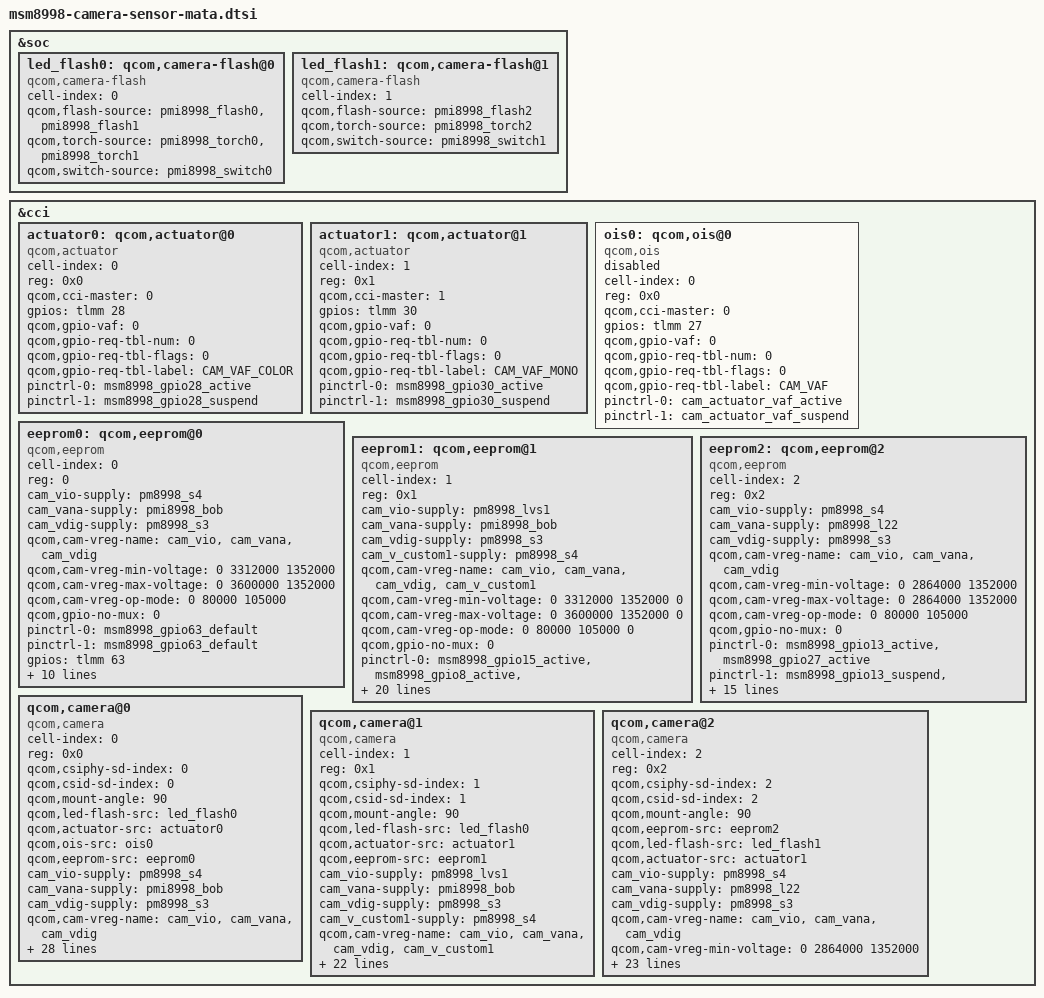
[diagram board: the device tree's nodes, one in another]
/*
 * Copyright (c) 2016, The Linux Foundation. All rights reserved.
 *
 * This program is free software; you can redistribute it and/or modify
 * it under the terms of the GNU General Public License version 2 and
 * only version 2 as published by the Free Software Foundation.
 *
 * This program is distributed in the hope that it will be useful,
 * but WITHOUT ANY WARRANTY; without even the implied warranty of
 * MERCHANTABILITY or FITNESS FOR A PARTICULAR PURPOSE.  See the
 * GNU General Public License for more details.
 */

&soc {
	led_flash0: qcom,camera-flash@0 {
		cell-index = <0>;
		compatible = "qcom,camera-flash";
		qcom,flash-source = <&pmi8998_flash0 &pmi8998_flash1>;
		qcom,torch-source = <&pmi8998_torch0 &pmi8998_torch1>;
		qcom,switch-source = <&pmi8998_switch0>;
		status = "ok";
	};

	led_flash1: qcom,camera-flash@1 {
		cell-index = <1>;
		compatible = "qcom,camera-flash";
		qcom,flash-source = <&pmi8998_flash2>;
		qcom,torch-source = <&pmi8998_torch2>;
		qcom,switch-source = <&pmi8998_switch1>;
		status = "ok";
	};
};

&cci {
	actuator0: qcom,actuator@0 {
		cell-index = <0>;
		reg = <0x0>;
		compatible = "qcom,actuator";
		qcom,cci-master = <0>;
		gpios = <&tlmm 28 0>;
		qcom,gpio-vaf = <0>;
		qcom,gpio-req-tbl-num = <0>;
		qcom,gpio-req-tbl-flags = <0>;
		qcom,gpio-req-tbl-label = "CAM_VAF_COLOR";
		pinctrl-names = "cam_default", "cam_suspend";
		pinctrl-0 = <&msm8998_gpio28_active>;
		pinctrl-1 = <&msm8998_gpio28_suspend>;
	};

	actuator1: qcom,actuator@1 {
		cell-index = <1>;
		reg = <0x1>;
		compatible = "qcom,actuator";
		qcom,cci-master = <1>;
		gpios = <&tlmm 30 0>;
		qcom,gpio-vaf = <0>;
		qcom,gpio-req-tbl-num = <0>;
		qcom,gpio-req-tbl-flags = <0>;
		qcom,gpio-req-tbl-label = "CAM_VAF_MONO";
		pinctrl-names = "cam_default", "cam_suspend";
		pinctrl-0 = <&msm8998_gpio30_active>;
		pinctrl-1 = <&msm8998_gpio30_suspend>;
	};

	ois0: qcom,ois@0 {
		cell-index = <0>;
		reg = <0x0>;
		compatible = "qcom,ois";
		qcom,cci-master = <0>;
		gpios = <&tlmm 27 0>;
		qcom,gpio-vaf = <0>;
		qcom,gpio-req-tbl-num = <0>;
		qcom,gpio-req-tbl-flags = <0>;
		qcom,gpio-req-tbl-label = "CAM_VAF";
		pinctrl-names = "cam_default", "cam_suspend";
		pinctrl-0 = <&cam_actuator_vaf_active>;
		pinctrl-1 = <&cam_actuator_vaf_suspend>;
		status = "disabled";
	};
 
	eeprom0: qcom,eeprom@0 {
		cell-index = <0>;
		reg = <0>;
		compatible = "qcom,eeprom";
		cam_vio-supply = <&pm8998_s4>;
		cam_vana-supply = <&pmi8998_bob>;
		cam_vdig-supply = <&pm8998_s3>;
		qcom,cam-vreg-name = "cam_vio", "cam_vana", "cam_vdig";
		qcom,cam-vreg-min-voltage = <0 3312000 1352000>;
		qcom,cam-vreg-max-voltage = <0 3600000 1352000>;
		qcom,cam-vreg-op-mode = <0 80000 105000>;
		qcom,gpio-no-mux = <0>;
		pinctrl-names = "cam_default", "cam_suspend";
		pinctrl-0 = <&msm8998_gpio63_default>;
		pinctrl-1 = <&msm8998_gpio63_default>;
		gpios =  <&tlmm 63 0>;
		qcom,gpio-vio = <0>;
		qcom,gpio-req-tbl-num = <0>;
		qcom,gpio-req-tbl-flags = <0>;
		qcom,gpio-req-tbl-label = "CAM_VIO";
		qcom,sensor-position = <0>;
		qcom,sensor-mode = <0>;
		qcom,cci-master = <0>;
		status = "ok";
		clocks = <&clock_mmss clk_mclk1_clk_src>,
				<&clock_mmss clk_mmss_camss_mclk1_clk>;
		clock-names = "cam_src_clk", "cam_clk";
		qcom,clock-rates = <24000000 0>;
	};
  
	eeprom1: qcom,eeprom@1 {
		cell-index = <1>;
		reg = <0x1>;
		compatible = "qcom,eeprom";
		cam_vio-supply = <&pm8998_lvs1>;
		cam_vana-supply = <&pmi8998_bob>;
		cam_vdig-supply = <&pm8998_s3>;
		cam_v_custom1-supply = <&pm8998_s4>;
		qcom,cam-vreg-name = "cam_vio", "cam_vana", "cam_vdig", "cam_v_custom1";
		qcom,cam-vreg-min-voltage = <0 3312000 1352000 0>;
		qcom,cam-vreg-max-voltage = <0 3600000 1352000 0>;
		qcom,cam-vreg-op-mode = <0 80000 105000 0>;
		qcom,gpio-no-mux = <0>;
		pinctrl-names = "cam_default", "cam_suspend";
		pinctrl-0 = <&msm8998_gpio15_active
				&msm8998_gpio8_active
				&msm8998_gpio31_default
				&msm8998_gpio90_default>;
		pinctrl-1 = <&msm8998_gpio15_suspend
				&msm8998_gpio8_suspend
				&msm8998_gpio31_default
				&msm8998_gpio90_default>;
		gpios = <&tlmm 15 0>,
			<&tlmm 8 0>,
			<&tlmm 31 0>,
			<&tlmm 90 0>;
		qcom,gpio-reset = <1>;
		qcom,gpio-vana = <2>;
		qcom,gpio-vdig = <3>;
		qcom,gpio-req-tbl-num = <0 1 2 3>;
		qcom,gpio-req-tbl-flags = <1 0 0 0>;
		qcom,gpio-req-tbl-label = "CAMIF_MCLK1",
					"CAM_RESET1",
					"CAM_VANA1",
					"CAM_VDIG1";
		qcom,sensor-position = <0>;
		qcom,sensor-mode = <0>;
		qcom,cci-master = <1>;
		status = "ok";
		clocks = <&clock_mmss clk_mclk2_clk_src>,
				<&clock_mmss clk_mmss_camss_mclk2_clk>;
		clock-names = "cam_src_clk", "cam_clk";
		qcom,clock-rates = <24000000 0>;
	};

	eeprom2: qcom,eeprom@2 {
		cell-index = <2>;
		reg = <0x2>;
		compatible = "qcom,eeprom";
		cam_vio-supply = <&pm8998_s4>;
		cam_vana-supply = <&pm8998_l22>;
		cam_vdig-supply = <&pm8998_s3>;
		qcom,cam-vreg-name = "cam_vio", "cam_vana", "cam_vdig";
		qcom,cam-vreg-min-voltage = <0 2864000 1352000>;
		qcom,cam-vreg-max-voltage = <0 2864000 1352000>;
		qcom,cam-vreg-op-mode = <0 80000 105000>;
		qcom,gpio-no-mux = <0>;
		pinctrl-names = "cam_default", "cam_suspend";
		pinctrl-0 = <&msm8998_gpio13_active
				&msm8998_gpio27_active>;
		pinctrl-1 = <&msm8998_gpio13_suspend
				&msm8998_gpio27_active>;
		gpios = <&tlmm 13 0>,
			<&tlmm 27 0>,
			<&tlmm 9 0>,
			<&tlmm 65 0>;
		qcom,gpio-reset = <1>;
		qcom,gpio-vio = <2>;
		qcom,gpio-vdig = <3>;
		qcom,gpio-req-tbl-num = <0 1 2 3>;
		qcom,gpio-req-tbl-flags = <1 0 0 0>;
		qcom,gpio-req-tbl-label = "CAMIF_MCLK2",
					"CAM_RESET2",
					"CAM_VIO2",
					"CAM_VDIG2";
		qcom,sensor-position = <1>;
		qcom,sensor-mode = <0>;
		qcom,cci-master = <1>;
		status = "ok";
		clocks = <&clock_mmss clk_mclk0_clk_src>,
				<&clock_mmss clk_mmss_camss_mclk0_clk>;
		clock-names = "cam_src_clk", "cam_clk";
		qcom,clock-rates = <24000000 0>;
	};
 
	qcom,camera@0 {
		cell-index = <0>;
		compatible = "qcom,camera";
		reg = <0x0>;
		qcom,csiphy-sd-index = <0>;
		qcom,csid-sd-index = <0>;
		qcom,mount-angle = <90>;
		qcom,led-flash-src = <&led_flash0>;
		qcom,actuator-src = <&actuator0>;
		qcom,ois-src = <&ois0>;
		qcom,eeprom-src = <&eeprom0>;
		cam_vio-supply = <&pm8998_s4>;
		cam_vana-supply = <&pmi8998_bob>;
		cam_vdig-supply = <&pm8998_s3>;
		qcom,cam-vreg-name = "cam_vio", "cam_vana", "cam_vdig";
		qcom,cam-vreg-min-voltage = <0 3312000 1352000>;
		qcom,cam-vreg-max-voltage = <0 3600000 1352000>;
		qcom,cam-vreg-op-mode = <0 80000 105000>;
		qcom,gpio-no-mux = <0>;
		pinctrl-names = "cam_default", "cam_suspend";
		pinctrl-0 = <&msm8998_gpio14_active
				 &msm8998_gpio29_active
				 &msm8998_gpio36_default
				 &msm8998_gpio39_default>;
		pinctrl-1 = <&msm8998_gpio14_suspend
				 &msm8998_gpio29_suspend
				 &msm8998_gpio36_default
				 &msm8998_gpio39_default>;
		gpios = <&tlmm 14 0>,
			<&tlmm 29 0>,
			<&tlmm 63 0>,
			<&tlmm 36 0>,
			<&tlmm 39 0>;
		qcom,gpio-reset = <1>;
		qcom,gpio-vio = <2>;
		qcom,gpio-vana = <3>;
		qcom,gpio-vdig = <4>;
		qcom,gpio-req-tbl-num = <0 1 2 3 4>;
		qcom,gpio-req-tbl-flags = <1 0 0 0 0>;
		qcom,gpio-req-tbl-label = "CAMIF_MCLK0",
					"CAM_RESET0",
					"CAM_VIO",
					"CAM_VANA",
					"CAM_VDIG";
		qcom,sensor-position = <0>;
		qcom,sensor-mode = <0>;
		qcom,cci-master = <0>;
		status = "ok";
		clocks = <&clock_mmss clk_mclk1_clk_src>,
				<&clock_mmss clk_mmss_camss_mclk1_clk>;
		clock-names = "cam_src_clk", "cam_clk";
		qcom,clock-rates = <24000000 0>;
	};

	qcom,camera@1 {
		cell-index = <1>;
		compatible = "qcom,camera";
		reg = <0x1>;
		qcom,csiphy-sd-index = <1>;
		qcom,csid-sd-index = <1>;
		qcom,mount-angle = <90>;
		qcom,led-flash-src = <&led_flash0>;
		qcom,actuator-src = <&actuator1>;
		qcom,eeprom-src = <&eeprom1>;
		cam_vio-supply = <&pm8998_lvs1>;
		cam_vana-supply = <&pmi8998_bob>;
		cam_vdig-supply = <&pm8998_s3>;
		cam_v_custom1-supply = <&pm8998_s4>;
		qcom,cam-vreg-name = "cam_vio", "cam_vana", "cam_vdig", "cam_v_custom1";
		qcom,cam-vreg-min-voltage = <0 3312000 1352000 0>;
		qcom,cam-vreg-max-voltage = <0 3600000 1352000 0>;
		qcom,cam-vreg-op-mode = <0 80000 105000 0>;
		qcom,gpio-no-mux = <0>;
		pinctrl-names = "cam_default", "cam_suspend";
		pinctrl-0 = <&msm8998_gpio15_active
				&msm8998_gpio8_active>;
		pinctrl-1 = <&msm8998_gpio15_suspend
				&msm8998_gpio8_suspend>;
		gpios = <&tlmm 15 0>,
			<&tlmm 8 0>,
			<&tlmm 31 0>,
			<&tlmm 90 0>;
		qcom,gpio-reset = <1>;
		qcom,gpio-vana = <2>;
		qcom,gpio-vdig = <3>;
		qcom,gpio-req-tbl-num = <0 1 2 3>;
		qcom,gpio-req-tbl-flags = <1 0 0 0>;
		qcom,gpio-req-tbl-label = "CAMIF_MCLK1",
					"CAM_RESET1",
					"CAM_VANA1",
					"CAM_VDIG1";
		qcom,sensor-position = <0>;
		qcom,sensor-mode = <0>;
		qcom,cci-master = <1>;
		status = "ok";
		clocks = <&clock_mmss clk_mclk2_clk_src>,
				<&clock_mmss clk_mmss_camss_mclk2_clk>;
		clock-names = "cam_src_clk", "cam_clk";
		qcom,clock-rates = <24000000 0>;
	};

	qcom,camera@2 {
		cell-index = <2>;
		compatible = "qcom,camera";
		reg = <0x2>;
		qcom,csiphy-sd-index = <2>;
		qcom,csid-sd-index = <2>;
		qcom,mount-angle = <90>;
		qcom,eeprom-src = <&eeprom2>;
		qcom,led-flash-src = <&led_flash1>;
		qcom,actuator-src = <&actuator1>;
		cam_vio-supply = <&pm8998_s4>;
		cam_vana-supply = <&pm8998_l22>;
		cam_vdig-supply = <&pm8998_s3>;
		qcom,cam-vreg-name = "cam_vio", "cam_vana", "cam_vdig";
		qcom,cam-vreg-min-voltage = <0 2864000 1352000>;
		qcom,cam-vreg-max-voltage = <0 2864000 1352000>;
		qcom,cam-vreg-op-mode = <0 80000 105000>;
		qcom,gpio-no-mux = <0>;
		pinctrl-names = "cam_default", "cam_suspend";
		pinctrl-0 = <&msm8998_gpio13_active
				&msm8998_gpio27_active
				&msm8998_gpio65_default>;
		pinctrl-1 = <&msm8998_gpio13_suspend
				&msm8998_gpio27_active
				&msm8998_gpio65_default>;
		gpios = <&tlmm 13 0>,
			<&tlmm 27 0>,
			<&tlmm 9 0>,
			<&tlmm 65 0>;
		qcom,gpio-reset = <1>;
		qcom,gpio-vio = <2>;
		qcom,gpio-vdig = <3>;
		qcom,gpio-req-tbl-num = <0 1 2 3>;
		qcom,gpio-req-tbl-flags = <1 0 0 0>;
		qcom,gpio-req-tbl-label = "CAMIF_MCLK2",
					"CAM_RESET2",
					"CAM_VIO2",
					"CAM_VDIG2";
		qcom,sensor-position = <1>;
		qcom,sensor-mode = <0>;
		qcom,cci-master = <1>;
		status = "ok";
		clocks = <&clock_mmss clk_mclk0_clk_src>,
				<&clock_mmss clk_mmss_camss_mclk0_clk>;
		clock-names = "cam_src_clk", "cam_clk";
		qcom,clock-rates = <24000000 0>;
	};
};
